# ADSP-2183xW_LPC register map
Vendor: Analog Devices; Series: ADSP-2183xW_LPC; File version: 3.0.3.517
CPU: 
Registers are 32-bit, read-write, reset 0x0 unless marked. A register's access mark holds for its fields unless they carry their own. Offsets are from the block's base; [hi:lo] are bit positions; {n}, {i} and the like mark numbered series.

## TRACE0
Base 0x3110B000
0x00 SSPSR reset 0xFFFFFFFF — Supported Port Size Register.
  [31:0] SSPSR ro
0x04 CSPSR reset 0x1 — Current Port Size Register.
  [31:0] CSPSR range 0x00000000..0xFFFFFFFF
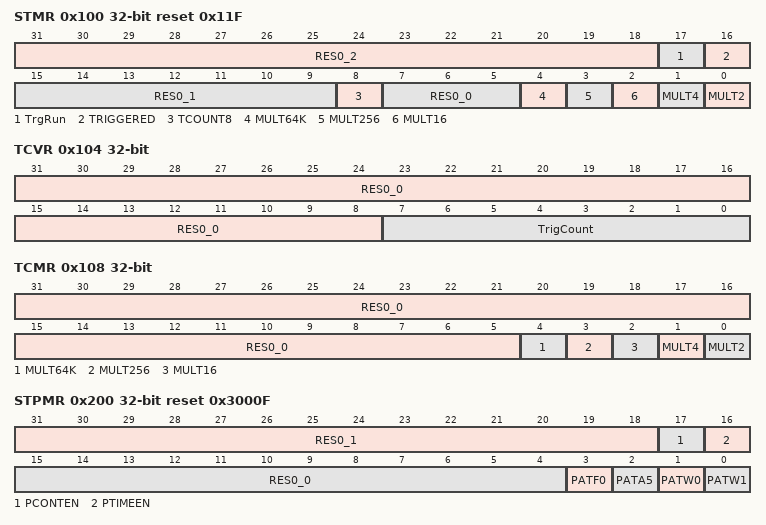
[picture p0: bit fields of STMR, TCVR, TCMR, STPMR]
0x100 STMR reset 0x11F — Supported Trigger Modes Register.
  [31:18] RES0_2 ro, [17] TrgRun ro, [16] TRIGGERED ro, [15:9] RES0_1 ro, [8] TCOUNT8 ro, [7:5] RES0_0 ro, [4] MULT64K ro, [3] MULT256 ro, [2] MULT16 ro, [1] MULT4 ro, [0] MULT2 ro
0x104 TCVR — Trigger Counter Value Register.
  [31:8] RES0_0 range 0x00000000..0x00FFFFFF, [7:0] TrigCount range 0x00000000..0x000000FF
0x108 TCMR — Trigger Counter Multiplier Register.
  [31:5] RES0_0 range 0x00000000..0x07FFFFFF, [4] MULT64K range 0x00000000..0x00000001, [3] MULT256 range 0x00000000..0x00000001, [2] MULT16 range 0x00000000..0x00000001, [1] MULT4 range 0x00000000..0x00000001, [0] MULT2 range 0x00000000..0x00000001
0x200 STPMR reset 0x3000F — Supported Test Patterns/Modes Register.
  [31:18] RES0_1 ro, [17] PCONTEN ro, [16] PTIMEEN ro, [15:4] RES0_0 ro, [3] PATF0 ro, [2] PATA5 ro, [1] PATW0 ro, [0] PATW1 ro
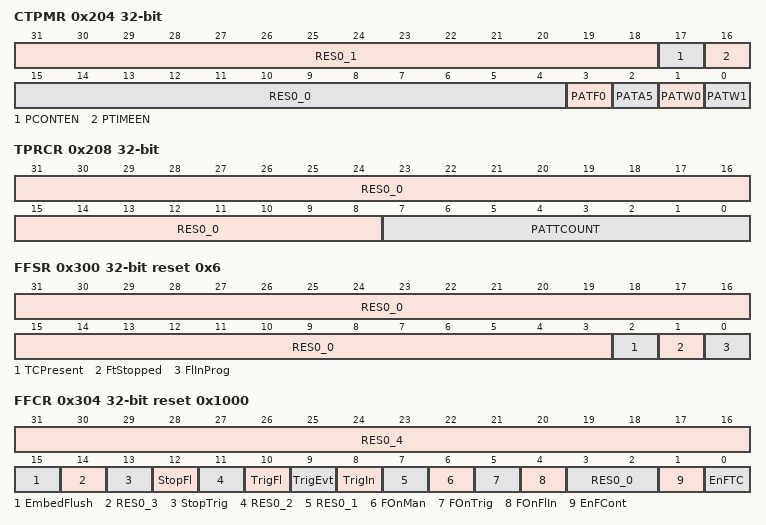
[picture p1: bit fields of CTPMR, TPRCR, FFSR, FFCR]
0x204 CTPMR — Current Test Patterns/Modes Register.
  [31:18] RES0_1 range 0x00000000..0x00003FFF, [17] PCONTEN range 0x00000000..0x00000001, [16] PTIMEEN range 0x00000000..0x00000001, [15:4] RES0_0 range 0x00000000..0x00000FFF, [3] PATF0 range 0x00000000..0x00000001, [2] PATA5 range 0x00000000..0x00000001, [1] PATW0 range 0x00000000..0x00000001, [0] PATW1 range 0x00000000..0x00000001
0x208 TPRCR — Test Pattern Repeat Counter Register.
  [31:8] RES0_0 range 0x00000000..0x00FFFFFF, [7:0] PATTCOUNT range 0x00000000..0x000000FF
0x300 FFSR reset 0x6 — Formatter and Flush Status Register.
  [31:3] RES0_0 ro, [2] TCPresent ro, [1] FtStopped ro, [0] FlInProg ro
0x304 FFCR reset 0x1000 — Formatter and Flush Control Register.
  [31:16] RES0_4 range 0x00000000..0x0000FFFF, [15] EmbedFlush range 0x00000000..0x00000001, [14] RES0_3 range 0x00000000..0x00000001, [13] StopTrig range 0x00000000..0x00000001, [12] StopFl range 0x00000000..0x00000001, [11] RES0_2 range 0x00000000..0x00000001, [10] TrigFl range 0x00000000..0x00000001, [9] TrigEvt range 0x00000000..0x00000001, [8] TrigIn range 0x00000000..0x00000001, [7] RES0_1 range 0x00000000..0x00000001, [6] FOnMan range 0x00000000..0x00000001, [5] FOnTrig range 0x00000000..0x00000001, [4] FOnFlIn range 0x00000000..0x00000001, [3:2] RES0_0 range 0x00000000..0x00000003, [1] EnFCont range 0x00000000..0x00000001, [0] EnFTC range 0x00000000..0x00000001
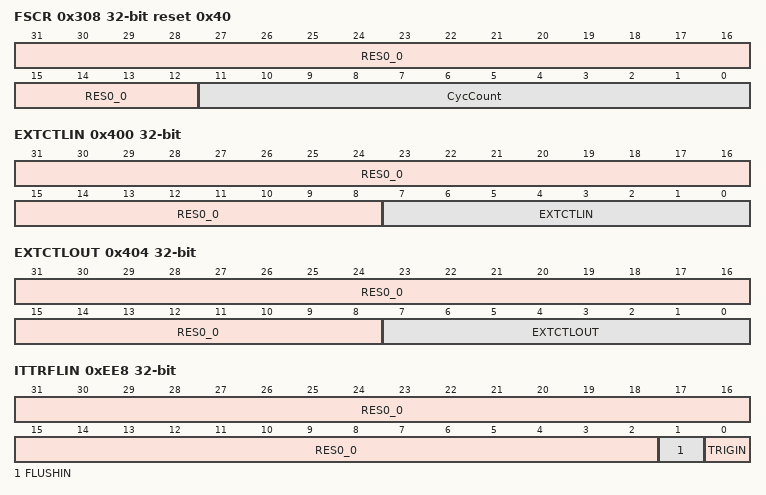
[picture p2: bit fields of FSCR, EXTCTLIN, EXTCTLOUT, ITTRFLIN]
0x308 FSCR reset 0x40 — Formatter Synchronization Count Register.
  [31:12] RES0_0 range 0x00000000..0x000FFFFF, [11:0] CycCount range 0x00000000..0x00000FFF
0x400 EXTCTLIN — External Control Port In Register.
  [31:8] RES0_0 ro, [7:0] EXTCTLIN ro
0x404 EXTCTLOUT — External Control Port Out Register.
  [31:8] RES0_0 range 0x00000000..0x00FFFFFF, [7:0] EXTCTLOUT range 0x00000000..0x000000FF
0xEE8 ITTRFLIN — Integration Test Trigger In and Flush In Register.
  [31:2] RES0_0 ro, [1] FLUSHIN ro, [0] TRIGIN ro
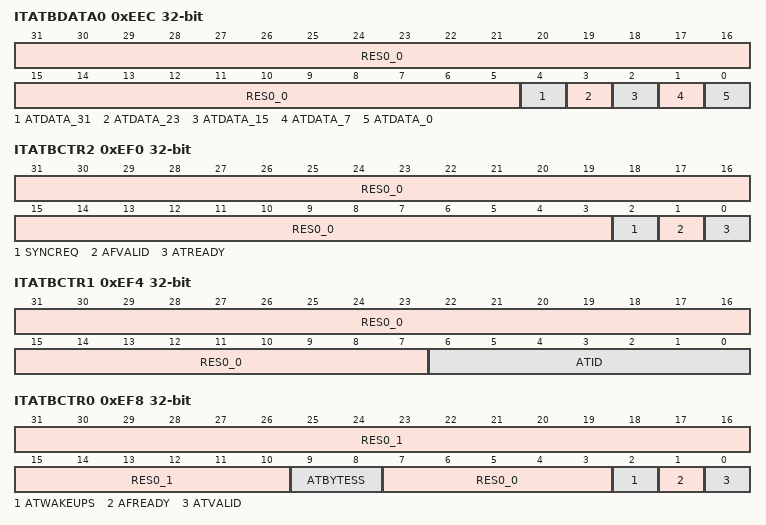
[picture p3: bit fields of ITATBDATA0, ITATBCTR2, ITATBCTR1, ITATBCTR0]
0xEEC ITATBDATA0 — Integration Test ATB Data Register 0.
  [31:5] RES0_0 ro, [4] ATDATA_31 ro, [3] ATDATA_23 ro, [2] ATDATA_15 ro, [1] ATDATA_7 ro, [0] ATDATA_0 ro
0xEF0 ITATBCTR2 — Integration Test ATB Control Register 2.
  [31:3] RES0_0 wo range 0x00000000..0x1FFFFFFF, [2] SYNCREQ wo range 0x00000000..0x00000001, [1] AFVALID wo range 0x00000000..0x00000001, [0] ATREADY wo range 0x00000000..0x00000001
0xEF4 ITATBCTR1 — Integration Test ATB Control Register 1.
  [31:7] RES0_0 ro, [6:0] ATID ro
0xEF8 ITATBCTR0 — Integration Test ATB Control Register 0.
  [31:10] RES0_1 ro, [9:8] ATBYTESS ro, [7:3] RES0_0 ro, [2] ATWAKEUPS ro, [1] AFREADY ro, [0] ATVALID ro
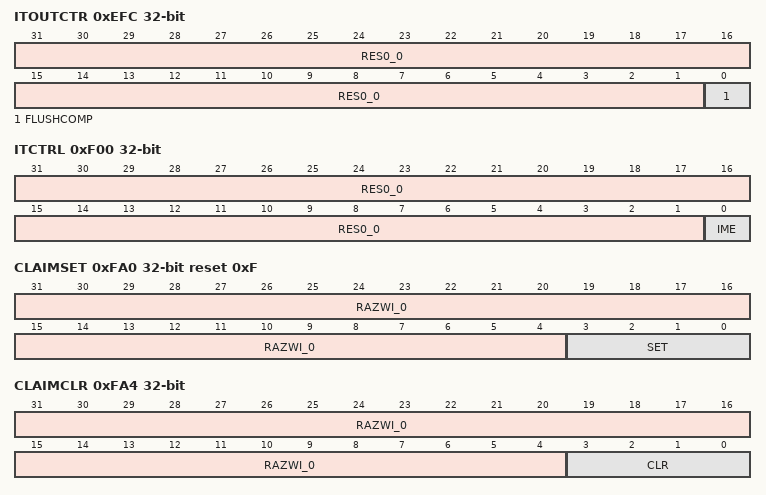
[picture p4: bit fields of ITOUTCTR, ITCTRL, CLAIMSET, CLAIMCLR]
0xEFC ITOUTCTR — Integration Test Output Control Register.
  [31:1] RES0_0 wo range 0x00000000..0x7FFFFFFF, [0] FLUSHCOMP wo range 0x00000000..0x00000001
0xF00 ITCTRL — Integration Mode Control Register.
  [31:1] RES0_0 range 0x00000000..0x7FFFFFFF, [0] IME range 0x00000000..0x00000001
0xFA0 CLAIMSET reset 0xF — Claim Tag Set Register.
  [31:4] RAZWI_0 range 0x00000000..0x0FFFFFFF, [3:0] SET range 0x00000000..0x0000000F
0xFA4 CLAIMCLR — Claim Tag Clear Register.
  [31:4] RAZWI_0 range 0x00000000..0x0FFFFFFF, [3:0] CLR range 0x00000000..0x0000000F
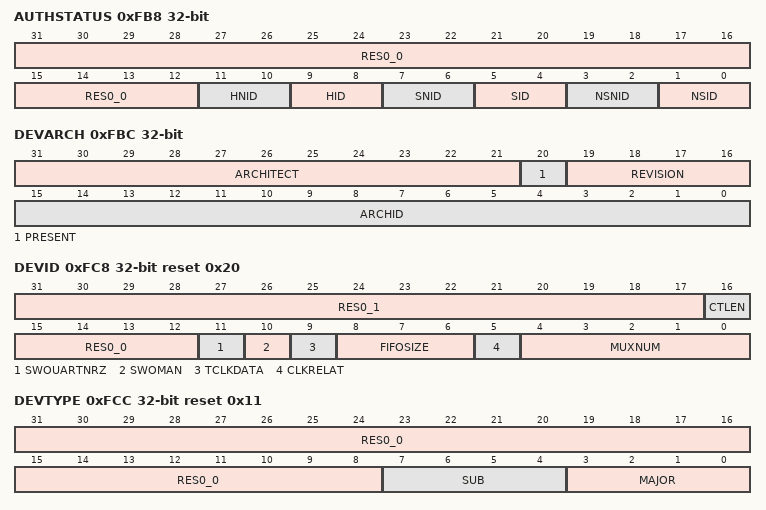
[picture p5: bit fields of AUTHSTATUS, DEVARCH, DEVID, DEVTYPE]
0xFB8 AUTHSTATUS — Authentication Status Register.
  [31:12] RES0_0 ro, [11:10] HNID ro, [9:8] HID ro, [7:6] SNID ro, [5:4] SID ro, [3:2] NSNID ro, [1:0] NSID ro
0xFBC DEVARCH — Device Architecture Register.
  [31:21] ARCHITECT ro, [20] PRESENT ro, [19:16] REVISION ro, [15:0] ARCHID ro
0xFC8 DEVID reset 0x20 — Device Configuration Register.
  [31:17] RES0_1 ro, [16] CTLEN ro, [15:12] RES0_0 ro, [11] SWOUARTNRZ ro, [10] SWOMAN ro, [9] TCLKDATA ro, [8:6] FIFOSIZE ro, [5] CLKRELAT ro, [4:0] MUXNUM ro
0xFCC DEVTYPE reset 0x11 — Device Type Identifier Register.
  [31:8] RES0_0 ro, [7:4] SUB ro, [3:0] MAJOR ro
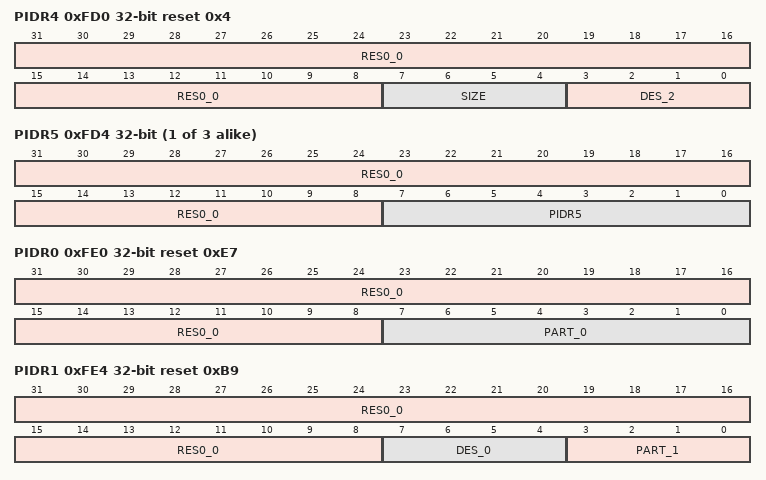
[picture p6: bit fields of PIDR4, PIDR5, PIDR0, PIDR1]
0xFD0 PIDR4 reset 0x4 — Peripheral Identification Register 4.
  [31:8] RES0_0 ro, [7:4] SIZE ro, [3:0] DES_2 ro
{0xFC0+4i} PIDR{i} (i=5..7) — Peripheral Identification Register {i}.
  [31:8] RES0_0 ro, [7:0] PIDR{i} ro
0xFE0 PIDR0 reset 0xE7 — Peripheral Identification Register 0.
  [31:8] RES0_0 ro, [7:0] PART_0 ro
0xFE4 PIDR1 reset 0xB9 — Peripheral Identification Register 1.
  [31:8] RES0_0 ro, [7:4] DES_0 ro, [3:0] PART_1 ro
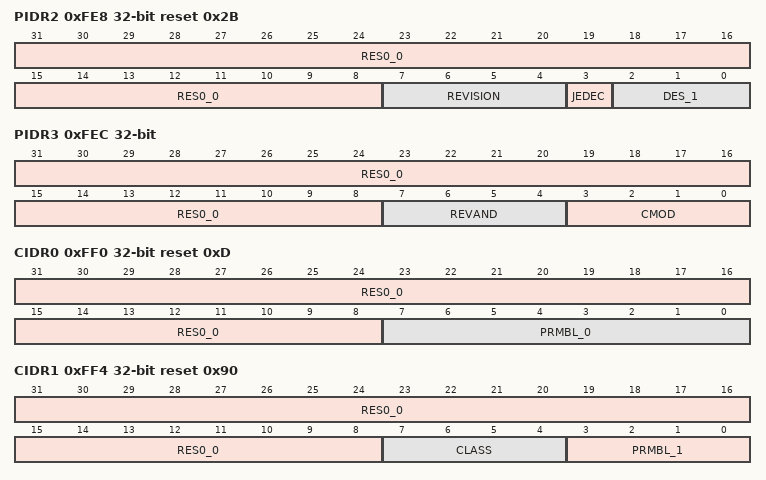
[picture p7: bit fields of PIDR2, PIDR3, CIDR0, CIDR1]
0xFE8 PIDR2 reset 0x2B — Peripheral Identification Register 2.
  [31:8] RES0_0 ro, [7:4] REVISION ro, [3] JEDEC ro, [2:0] DES_1 ro
0xFEC PIDR3 — Peripheral Identification Register 3.
  [31:8] RES0_0 ro, [7:4] REVAND ro, [3:0] CMOD ro
0xFF0 CIDR0 reset 0xD — Component Identification Register 0.
  [31:8] RES0_0 ro, [7:0] PRMBL_0 ro
0xFF4 CIDR1 reset 0x90 — Component Identification Register 1.
  [31:8] RES0_0 ro, [7:4] CLASS ro, [3:0] PRMBL_1 ro
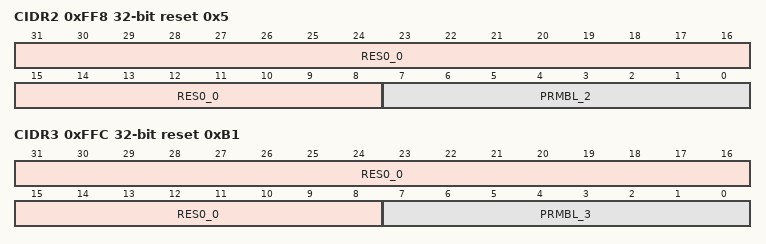
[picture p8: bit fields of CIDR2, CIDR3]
0xFF8 CIDR2 reset 0x5 — Component Identification Register 2.
  [31:8] RES0_0 ro, [7:0] PRMBL_2 ro
0xFFC CIDR3 reset 0xB1 — Component Identification Register 3.
  [31:8] RES0_0 ro, [7:0] PRMBL_3 ro
